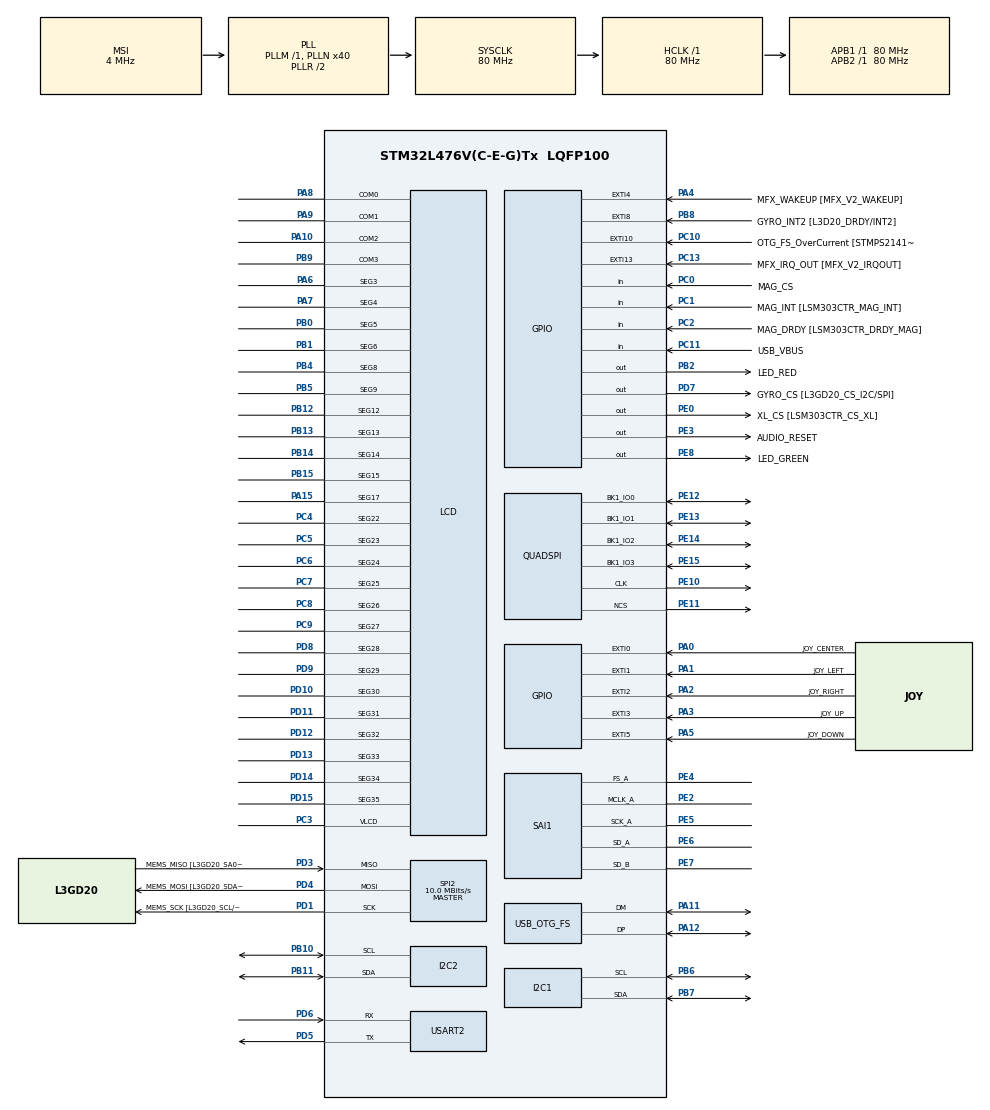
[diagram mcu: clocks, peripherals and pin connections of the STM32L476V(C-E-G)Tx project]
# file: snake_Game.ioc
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Dma.Request0=SAI1_A
Dma.SAI1_A.0.Direction=DMA_MEMORY_TO_PERIPH
Dma.SAI1_A.0.Instance=DMA2_Channel1
Dma.SAI1_A.0.MemDataAlignment=DMA_MDATAALIGN_HALFWORD
Dma.SAI1_A.0.MemInc=DMA_MINC_ENABLE
Dma.SAI1_A.0.Mode=DMA_CIRCULAR
Dma.SAI1_A.0.PeriphDataAlignment=DMA_PDATAALIGN_HALFWORD
Dma.SAI1_A.0.PeriphInc=DMA_PINC_DISABLE
Dma.SAI1_A.0.Priority=DMA_PRIORITY_HIGH
FATFS._FS_TINY=1
FATFS._MAX_SS=4096
FATFS._MIN_SS=4096
FATFS._USE_FIND=1
FATFS._USE_LABEL=1
FREERTOS.Mutexes01=qspiMutex,Dynamic,NULL
FREERTOS.Queues01=joystickInputQueue,1,uint16_t,0,Dynamic,NULL,NULL
FREERTOS.Tasks01=gameTask,0,4096,gameTaskBody,Default,NULL,Dynamic,NULL,NULL;usbTask,2,256,usbTaskBody,Default,NULL,Dynamic,NULL,NULL;audioTask,0,1024,audioTaskBody,Default,NULL,Dynamic,NULL,NULL;inputTask,0,128,inputTaskBody,Default,NULL,Dynamic,NULL,NULL
FREERTOS.configTOTAL_HEAP_SIZE=32768
I2C1.I2C_Coeff_DF=0
I2C1.I2C_Fall_Time=20
I2C1.I2C_Rise_Time=640
I2C1.Timing=0x40E03E53
I2C2.Timing=0x10909CEC
LCD.Bias=LCD_BIAS_1_3
LCD.Contrast=LCD_CONTRASTLEVEL_5
LCD.Divider=LCD_DIVIDER_31
Mcu.Family=STM32L4
Mcu.Name=STM32L476V(C-E-G)Tx
Mcu.Package=LQFP100
Mcu.UserConstants=A,0x1;B,0x2
NVIC.DMA2_Channel1_IRQn=true\:5\:0\:false\:false\:true\:true\:true\:true
NVIC.EXTI0_IRQn=true\:5\:0\:false\:false\:true\:true\:true\:true
NVIC.EXTI1_IRQn=true\:5\:0\:false\:false\:true\:true\:true\:true
NVIC.EXTI2_IRQn=true\:5\:0\:false\:false\:true\:true\:true\:true
NVIC.EXTI3_IRQn=true\:5\:0\:false\:false\:true\:true\:true\:true
NVIC.EXTI9_5_IRQn=true\:5\:0\:false\:false\:true\:true\:true\:true
NVIC.OTG_FS_IRQn=true\:5\:0\:false\:false\:true\:true\:true\:true
NVIC.PriorityGroup=NVIC_PRIORITYGROUP_4
NVIC.TIM1_UP_TIM16_IRQn=true\:0\:0\:false\:false\:true\:false\:false\:true
NVIC.TimeBase=TIM1_UP_TIM16_IRQn
NVIC.TimeBaseIP=TIM1
PA0.GPIO_Label=JOY_CENTER
PA0.GPIO_PuPd=GPIO_PULLDOWN
PA0.Signal=GPXTI0
PA1.GPIO_Label=JOY_LEFT
PA1.GPIO_PuPd=GPIO_PULLDOWN
PA1.Signal=GPXTI1
PA10.Mode=1/4 Duty Cycle
PA10.Signal=LCD_COM2
PA11.Mode=Device_Only
PA11.Signal=USB_OTG_FS_DM
PA12.Mode=Device_Only
PA12.Signal=USB_OTG_FS_DP
PA13\ (JTMS-SWDIO).Mode=Trace_Asynchronous_SW
PA13\ (JTMS-SWDIO).Signal=SYS_JTMS-SWDIO
PA14\ (JTCK-SWCLK).Mode=Trace_Asynchronous_SW
PA14\ (JTCK-SWCLK).Signal=SYS_JTCK-SWCLK
PA15\ (JTDI).Mode=SEG17
PA15\ (JTDI).Signal=LCD_SEG17
PA2.GPIO_Label=JOY_RIGHT
PA2.GPIO_PuPd=GPIO_PULLDOWN
PA2.Signal=GPXTI2
PA3.GPIO_Label=JOY_UP
PA3.GPIO_PuPd=GPIO_PULLDOWN
PA3.Signal=GPXTI3
PA4.GPIO_Label=MFX_WAKEUP [MFX_V2_WAKEUP] 
PA4.Signal=GPXTI4
PA5.GPIO_Label=JOY_DOWN
PA5.GPIO_PuPd=GPIO_PULLDOWN
PA5.Signal=GPXTI5
PA6.Mode=SEG3
PA6.Signal=LCD_SEG3
PA7.Mode=SEG4
PA7.Signal=LCD_SEG4
PA8.Mode=1/4 Duty Cycle
PA8.Signal=LCD_COM0
PA9.Mode=1/4 Duty Cycle
PA9.Signal=LCD_COM1
PB0.Mode=SEG5
PB0.Signal=LCD_SEG5
PB1.Mode=SEG6
PB1.Signal=LCD_SEG6
PB10.Mode=I2C
PB10.Signal=I2C2_SCL
PB11.Mode=I2C
PB11.Signal=I2C2_SDA
PB12.Mode=SEG12
PB12.Signal=LCD_SEG12
PB13.Mode=SEG13
PB13.Signal=LCD_SEG13
PB14.Mode=SEG14
PB14.Signal=LCD_SEG14
PB15.Mode=SEG15
PB15.Signal=LCD_SEG15
PB2.GPIO_Label=LED_RED
PB2.GPIO_PuPd=GPIO_PULLUP
PB2.Signal=GPIO_Output
PB3\ (JTDO-TRACESWO).Mode=Trace_Asynchronous_SW
PB3\ (JTDO-TRACESWO).Signal=SYS_JTDO-SWO
PB4\ (NJTRST).Mode=SEG8
PB4\ (NJTRST).Signal=LCD_SEG8
PB5.Mode=SEG9
PB5.Signal=LCD_SEG9
PB6.Mode=I2C
PB6.Signal=I2C1_SCL
PB7.Mode=I2C
PB7.Signal=I2C1_SDA
PB8.GPIO_Label=GYRO_INT2 [L3D20_DRDY/INT2] 
PB8.GPIO_ModeDefaultEXTI=GPIO_MODE_EVT_RISING
PB8.Signal=GPXTI8
PB9.Mode=1/4 Duty Cycle
PB9.Signal=LCD_COM3
PC0.GPIO_Label=MAG_CS
PC0.Signal=GPIO_Input
PC1.GPIO_Label=MAG_INT [LSM303CTR_MAG_INT] 
PC1.Signal=GPIO_Input
PC10.GPIO_Label=OTG_FS_OverCurrent [STMPS2141STR_FAULT] 
PC10.Signal=GPXTI10
PC11.GPIO_Label=USB_VBUS
PC11.Signal=GPIO_Input
PC13.GPIO_Label=MFX_IRQ_OUT [MFX_V2_IRQOUT] 
PC13.Signal=GPXTI13
PC14-OSC32_IN\ (PC14).Mode=LSE-External-Oscillator
PC14-OSC32_IN\ (PC14).Signal=RCC_OSC32_IN
PC15-OSC32_OUT\ (PC15).Mode=LSE-External-Oscillator
PC15-OSC32_OUT\ (PC15).Signal=RCC_OSC32_OUT
PC2.GPIO_Label=MAG_DRDY [LSM303CTR_DRDY_MAG] 
PC2.Signal=GPIO_Input
PC3.Mode=1/4 Duty Cycle
PC3.Signal=LCD_VLCD
PC4.Mode=SEG22
PC4.Signal=LCD_SEG22
PC5.Mode=SEG23
PC5.Signal=LCD_SEG23
PC6.Mode=SEG24
PC6.Signal=LCD_SEG24
PC7.Mode=SEG25
PC7.Signal=LCD_SEG25
PC8.Mode=SEG26
PC8.Signal=LCD_SEG26
PC9.Mode=SEG27
PC9.Signal=LCD_SEG27
PD1.GPIO_Label=MEMS_SCK [L3GD20_SCL/SPC] 
PD1.Mode=Full_Duplex_Master
PD1.Signal=SPI2_SCK
PD10.Mode=SEG30
PD10.Signal=LCD_SEG30
PD11.Mode=SEG31
PD11.Signal=LCD_SEG31
PD12.Mode=SEG32
PD12.Signal=LCD_SEG32
PD13.Mode=SEG33
PD13.Signal=LCD_SEG33
PD14.Mode=SEG34
PD14.Signal=LCD_SEG34
PD15.Mode=SEG35
PD15.Signal=LCD_SEG35
PD3.GPIO_Label=MEMS_MISO [L3GD20_SA0/SDO] 
PD3.Mode=Full_Duplex_Master
PD3.Signal=SPI2_MISO
PD4.GPIO_Label=MEMS_MOSI [L3GD20_SDA/SDI/SDO] 
PD4.Mode=Full_Duplex_Master
PD4.Signal=SPI2_MOSI
PD5.Mode=Asynchronous
PD5.Signal=USART2_TX
PD6.Mode=Asynchronous
PD6.Signal=USART2_RX
PD7.GPIO_Label=GYRO_CS [L3GD20_CS_I2C/SPI] 
PD7.Signal=GPIO_Output
PD8.Mode=SEG28
PD8.Signal=LCD_SEG28
PD9.Mode=SEG29
PD9.Signal=LCD_SEG29
PE0.GPIO_Label=XL_CS [LSM303CTR_CS_XL] 
PE0.Signal=GPIO_Output
PE10.Mode=Single Bank
PE10.Signal=QUADSPI_CLK
PE11.Mode=Single Bank
PE11.Signal=QUADSPI_NCS
PE12.Mode=Single Bank
PE12.Signal=QUADSPI_BK1_IO0
PE13.Mode=Single Bank
PE13.Signal=QUADSPI_BK1_IO1
PE14.Mode=Single Bank
PE14.Signal=QUADSPI_BK1_IO2
PE15.Mode=Single Bank
PE15.Signal=QUADSPI_BK1_IO3
PE2.Mode=SAI_A_MasterWithClock
PE2.Signal=SAI1_MCLK_A
PE3.GPIO_Label=AUDIO_RESET
PE3.Signal=GPIO_Output
PE4.Mode=SAI_A_MasterWithClock
PE4.Signal=SAI1_FS_A
PE5.Mode=SAI_A_MasterWithClock
PE5.Signal=SAI1_SCK_A
PE6.Mode=SAI_A_MasterWithClock
PE6.Signal=SAI1_SD_A
PE7.Mode=SAI_B_SyncSlave
PE7.Signal=SAI1_SD_B
PE8.GPIO_Label=LED_GREEN
PE8.GPIO_PuPd=GPIO_PULLUP
PE8.Signal=GPIO_Output
ProjectManager.HeapSize=0x200
ProjectManager.StackSize=0x400
ProjectManager.TargetToolchain=STM32CubeIDE
QUADSPI.ClockPrescaler-Single\ Bank=255
QUADSPI.FifoThreshold-Single\ Bank=1
QUADSPI.FlashSize-Single\ Bank=0x17
RCC.ADCFreq_Value=96000000
RCC.AHBFreq_Value=80000000
RCC.APB1Freq_Value=80000000
RCC.APB1TimFreq_Value=80000000
RCC.APB2Freq_Value=80000000
RCC.APB2TimFreq_Value=80000000
RCC.CortexFreq_Value=80000000
RCC.HCLKFreq_Value=80000000
RCC.HSE_VALUE=8000000
RCC.HSI_VALUE=16000000
RCC.MSIClockRange=RCC_MSIRANGE_6
RCC.MSI_VALUE=4000000
RCC.PLLN=40
RCC.PLLSAI1N=48
RCC.PLLSAI1P=RCC_PLLP_DIV17
RCC.PLLSAI1Q=RCC_PLLQ_DIV4
RCC.RTCClockSelection=RCC_RTCCLKSOURCE_LSE
RCC.SYSCLKFreq_VALUE=80000000
RCC.SYSCLKSource=RCC_SYSCLKSOURCE_PLLCLK
RCC.USBFreq_Value=48000000
RCC.VCOOutputFreq_Value=160000000
SAI1.ActiveFrameLength-SAI_A_MasterWithClock=16
SAI1.AudioFrequency-SAI_A_MasterWithClock=SAI_AUDIO_FREQUENCY_44K
SAI1.ClockStrobing-SAI_A_MasterWithClock=SAI_CLOCKSTROBING_RISINGEDGE
SAI1.DataSize-SAI_A_MasterWithClock=SAI_DATASIZE_16
SAI1.ErrorAudioFreq-SAI_A_MasterWithClock=0.26 %
SAI1.FIFOThreshold-SAI_A_MasterWithClock=SAI_FIFOTHRESHOLD_1QF
SAI1.FSDefinition-SAI_A_MasterWithClock=SAI_FS_CHANNEL_IDENTIFICATION
SAI1.FSOffset-SAI_A_MasterWithClock=SAI_FS_BEFOREFIRSTBIT
SAI1.FrameLength-SAI_A_MasterWithClock=32
SAI1.FrameLength-SAI_B_SyncSlave=32
SAI1.Instance-SAI_A_MasterWithClock=SAI$Index_Block_A
SAI1.Instance-SAI_B_SyncSlave=SAI$Index_Block_B
SAI1.MClockEnable-SAI_A_MasterWithClock=SAI_MASTERCLOCK_ENABLE
SAI1.OutputDrive-SAI_A_MasterWithClock=SAI_OUTPUTDRIVE_ENABLE
SAI1.RealAudioFreq-SAI_A_MasterWithClock=44.117 KHz
SAI1.SlotActive-SAI_A_MasterWithClock=0x00000003
SAI1.SlotNumber-SAI_A_MasterWithClock=2
SAI1.VirtualMode-SAI_A_MasterWithClock=VM_MASTER
SAI1.VirtualMode-SAI_B_SyncSlave=VM_SLAVE
SAI1.VirtualSlotActive-SAI_A_MasterWithClock=SAI_SLOT_USERSETTING
SAI1.VirtualSlotActive0-SAI_A_MasterWithClock=true
SAI1.VirtualSlotActive1-SAI_A_MasterWithClock=true
SPI2.BaudRatePrescaler=SPI_BAUDRATEPRESCALER_8
SPI2.CalculateBaudRate=10.0 MBits/s
SPI2.DataSize=SPI_DATASIZE_8BIT
SPI2.Direction=SPI_DIRECTION_2LINES
SPI2.Mode=SPI_MODE_MASTER
SPI2.VirtualType=VM_MASTER
USART2.VirtualMode-Asynchronous=VM_ASYNC
USB_DEVICE.CLASS_NAME_FS=MSC
USB_DEVICE.MSC_MEDIA_PACKET=4096
USB_DEVICE.USBD_LPM_ENABLED=0
USB_DEVICE.VirtualMode=Msc
USB_DEVICE.VirtualModeFS=Msc_FS
USB_OTG_FS.VirtualMode=Device_Only
VP_FATFS_VS_Generic.Mode=User_defined
VP_FREERTOS_VS_CMSIS_V1.Mode=CMSIS_V1
VP_SYS_VS_tim1.Mode=TIM1
VP_USB_DEVICE_VS_USB_DEVICE_MSC_FS.Mode=MSC_FS
board=Audio_player2

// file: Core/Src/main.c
/* USER CODE BEGIN Header */
/**
 ******************************************************************************
 * @file           : main.c
 * @brief          : Main program body
 ******************************************************************************
 * @attention
 *
 * <h2><center>&copy; Copyright (c) 2020 STMicroelectronics.
 * All rights reserved.</center></h2>
 *
 * This software component is licensed by ST under Ultimate Liberty license
 * SLA0044, the "License"; You may not use this file except in compliance with
 * the License. You may obtain a copy of the License at:
 *                             www.st.com/SLA0044
 *
 ******************************************************************************
 */
/* USER CODE END Header */

#include "main.h"
#include "cmsis_os.h"
#include "dma.h"
#include "fatfs.h"
#include "i2c.h"
#include "lcd.h"
#include "quadspi.h"
#include "sai.h"
#include "spi.h"
#include "usart.h"
#include "usb_device.h"
#include "gpio.h"

/* USER CODE BEGIN Includes */
// ***** Librerías comunes *****
#include <stdio.h>
#include <string.h>
#include <stdlib.h>
#include <stdbool.h>
#include <time.h>

// ***** Librerías del BSP *****
#include "stm32l476g_discovery.h"
#include "stm32l476g_discovery_glass_lcd.h"
#include "stm32l476g_discovery_compass.h"
#include "stm32l476g_discovery_gyroscope.h"

// ***** Librerías de la pantalla oled *****
#include "ssd1306.h"
//#include "ssd1306_tests.h"

/* USER CODE END Includes */

/* USER CODE BEGIN PV */
// ***** Parámetros de la pantalla *****
const int width = 128;
const int height = 64;

// ***** Parámetros del menu *****
SSD1306_COLOR color = Black;	// Color de fondo del texto
int menu = 0;	// Indice del menu

// ***** Parámetros del juego *****
bool gameover;	// Bandera de Game Over
int x, y, score;	// Coordenadas de la pantalla y variable para los puntos
int fruitX[3], fruitY[3];	// Arrays con las coordenadas de las frutas
int snakeX[256], snakeY[256]; // Arrays con las coordenadas del cuerpo de la serpiente
int nTail;	// Número de pixeles que forman la cola de la serpiente
int state, prev_state;	// Estado en el que nos encontramos y el anterior a este

// ***** Variables del sistema de archivos Fat y del USB *****
FIL                     File;						// Handle del archivo
FATFS                   FatFs;						// Handle del sistema de archivos

/* USER CODE END PV */

void SystemClock_Config(void);
void MX_FREERTOS_Init(void);
/* USER CODE BEGIN PFP */

// ***** Funciones de Audio *****
void AudioPlayer_Start(const TCHAR* file_name, bool bg_music, bool aflag);

// ***** Funciones del Juego *****
void Setup();		// Función para establecer las condiciones iniciales
void DrawOled();	// Función para dibujar la pantalla oled
void Algoritmo();	// Función que controla la ejecución del juego
void Fruta();		// Función para crear las frutas en la pantalla
void GameOver();	// Función para el estado de Game Over
void Leaderboard();	// Función para mostrar las mejores puntuaciones conseguidas
/* USER CODE END PFP */

int main(void)
{

  /* MCU Configuration--------------------------------------------------------*/

  /* Reset of all peripherals, Initializes the Flash interface and the Systick. */
  HAL_Init();

  /* Configure the system clock */
  SystemClock_Config();

  /* Initialize all configured peripherals */
  MX_GPIO_Init();
  MX_DMA_Init();
  MX_I2C1_Init();
  MX_I2C2_Init();
  MX_LCD_Init();
  MX_QUADSPI_Init();
  MX_SAI1_Init();
  MX_SPI2_Init();
  MX_USART2_UART_Init();
  MX_FATFS_Init();
  /* USER CODE BEGIN 2 */

  // Inicializamos los módulos BSP
  //BSP_COMPASS_Init();
  BSP_GYRO_Init();
  BSP_LCD_GLASS_Init();

  /* USER CODE END 2 */

  /* Call init function for freertos objects (in freertos.c) */
  MX_FREERTOS_Init();
  /* Start scheduler */
  //osKernelStart();

  /* We should never get here as control is now taken by the scheduler */
  /* Infinite loop */
  /* USER CODE BEGIN WHILE */

  // Mostramos la pantalla de inicio
	ssd1306_Init();	// Iniciamos la comunicación con la pantalla oled
	ssd1306_Fill(Black);	// Dibujamos toda la pantalla de negro
	ssd1306_SetCursor(24, 4);	// Situamos el cursor en las coordenadas indicadas
	ssd1306_WriteString("SNAKE", Font_16x26, White);	// Escribimos el string con la fuente
	ssd1306_SetCursor(24, 34);						 	// y el color indicado
	ssd1306_WriteString("START", Font_16x26, White);	// Repetimos para cada string
	ssd1306_UpdateScreen();	// Actualizamos la pantalla con lo que hemos dibujado

	while (1)
	{
    /* USER CODE END WHILE */

    /* USER CODE BEGIN 3 */

		// ***** Pantalla de Inicio *****
		if (menu == 0)
		{
			for(int i = 0; i < 100; i++)	// Realizamos una espera de 500 ms
			{
				JOYState_TypeDef JoyState = BSP_JOY_GetState();	// Obetenemos la entrada del DPAD

				if(JoyState == JOY_SEL){	// Si el usuario pulsa el botón central mostramos el menú
					menu = 1;	// Cambiamos el índice del menú para indicar que hemos entrado
					ssd1306_Fill(Black);	// Y dibujamos el menú de inicio
					ssd1306_SetCursor(42, 1);
					ssd1306_WriteString("MENU", Font_11x18, White);
					ssd1306_SetCursor(13, 20);
					ssd1306_WriteString("DPAD", Font_11x18, White);
					ssd1306_SetCursor(70, 20);
					ssd1306_WriteString("GYRO", Font_11x18, White);
					ssd1306_SetCursor(31, 40);
					ssd1306_WriteString("SCORES", Font_11x18, White);
					ssd1306_UpdateScreen();
					HAL_Delay(100);
					break;
				}
				HAL_Delay(5);
			}

			if(menu == 0)	// Cada 500 ms cambiamos el color de fondo del botón START
			{
				ssd1306_SetCursor(24, 34);
				ssd1306_WriteString("START", Font_16x26, color);
				ssd1306_UpdateScreen();
			}

			if (color == Black)	// Con este IF intercambiamos el color de fondo
				color = White;	// del botón de START para crear el efecto de intermitencia
			else
				color = Black;
		}
		else // ***** Menu principal *****
		{
			JOYState_TypeDef JoyState = BSP_JOY_GetState();

			switch(JoyState) {	// Leemos el valor de entrada del DPAD y cambiamos
			case JOY_LEFT:		// la selección del menú de acuerdo a eso
				if(menu == 2)
					menu = 1;
				break;
			case JOY_RIGHT:
				if(menu == 1)
					menu = 2;
				break;
			case JOY_UP:
				if(menu == 3)
					menu = 1;
				break;
			case JOY_DOWN:
				if(menu == 1 || menu == 2)
					menu = 3;
				break;
			case JOY_SEL:
				if(menu == 1)			// Si estamos en la opción 1 ejecutamos el juego usando
				{						// como entrada el DPAD para jugar
					HAL_Delay(100);
					Setup();
					DrawOled();			// Dibujamos la pantalla de juego
					osKernelStart();	// e iniciamos el planificador
				}
				else if(menu == 2)		// Si estamos en la opción 2 ejecutamos el juego usando
				{						// como entrada el Giroscopio o el Acelerómetro para jugar
					HAL_Delay(100);
					Setup();
					DrawOled();			// Dibujamos la pantalla de juego
					osKernelStart();	// e iniciamos el planificador
				}
				else if(menu == 3)		// Si estamos en la opción 3 ejecutamos la función para
				{						// mostrar las mejores puntuaciones que estén guardadas
					HAL_Delay(100);
					Leaderboard();
				}
				break;
			default:	// Si no hay entrada, no ejecutamos nada
				break;
			}

			if(menu == 1)	// Mostramos la opción de DPAD como seleccionada
			{
				ssd1306_Fill(Black);
				ssd1306_SetCursor(42, 1);
				ssd1306_WriteString("MENU", Font_11x18, White);
				ssd1306_SetCursor(13, 20);
				ssd1306_WriteString("DPAD", Font_11x18, Black);
				ssd1306_SetCursor(70, 20);
				ssd1306_WriteString("GYRO", Font_11x18, White);
				ssd1306_SetCursor(31, 40);
				ssd1306_WriteString("SCORES", Font_11x18, White);
				ssd1306_UpdateScreen();
			}
			else if(menu == 2)	// Mostramos la opción de GYRO como seleccionada
			{
				ssd1306_Fill(Black);
				ssd1306_SetCursor(42, 1);
				ssd1306_WriteString("MENU", Font_11x18, White);
				ssd1306_SetCursor(13, 20);
				ssd1306_WriteString("DPAD", Font_11x18, White);
				ssd1306_SetCursor(70, 20);
				ssd1306_WriteString("GYRO", Font_11x18, Black);
				ssd1306_SetCursor(31, 40);
				ssd1306_WriteString("SCORES", Font_11x18, White);
				ssd1306_UpdateScreen();
			}
			else if(menu == 3)	// Mostramos la opción de SCORES como seleccionada
			{
				ssd1306_Fill(Black);
				ssd1306_SetCursor(42, 1);
				ssd1306_WriteString("MENU", Font_11x18, White);
				ssd1306_SetCursor(13, 20);
				ssd1306_WriteString("DPAD", Font_11x18, White);
				ssd1306_SetCursor(70, 20);
				ssd1306_WriteString("GYRO", Font_11x18, White);
				ssd1306_SetCursor(31, 40);
				ssd1306_WriteString("SCORES", Font_11x18, Black);
				ssd1306_UpdateScreen();
			}
		}

		// Comprobamos si se ha conectado el USB, y en caso de que sí iniciamos el scheduler
		if ((HAL_GPIO_ReadPin(USB_VBUS_GPIO_Port, USB_VBUS_Pin) != GPIO_PIN_RESET) && menu == 0)
		{
			osKernelStart();
		}

	}
  /* USER CODE END 3 */
}

void SystemClock_Config(void)
{
  RCC_OscInitTypeDef RCC_OscInitStruct = {0};
  RCC_ClkInitTypeDef RCC_ClkInitStruct = {0};
  RCC_PeriphCLKInitTypeDef PeriphClkInit = {0};

  /** Configure LSE Drive Capability
  */
  HAL_PWR_EnableBkUpAccess();
  __HAL_RCC_LSEDRIVE_CONFIG(RCC_LSEDRIVE_LOW);
  /** Initializes the CPU, AHB and APB busses clocks
  */
  RCC_OscInitStruct.OscillatorType = RCC_OSCILLATORTYPE_LSE|RCC_OSCILLATORTYPE_MSI;
  RCC_OscInitStruct.LSEState = RCC_LSE_ON;
  RCC_OscInitStruct.MSIState = RCC_MSI_ON;
  RCC_OscInitStruct.MSICalibrationValue = 0;
  RCC_OscInitStruct.MSIClockRange = RCC_MSIRANGE_6;
  RCC_OscInitStruct.PLL.PLLState = RCC_PLL_ON;
  RCC_OscInitStruct.PLL.PLLSource = RCC_PLLSOURCE_MSI;
  RCC_OscInitStruct.PLL.PLLM = 1;
  RCC_OscInitStruct.PLL.PLLN = 40;
  RCC_OscInitStruct.PLL.PLLP = RCC_PLLP_DIV7;
  RCC_OscInitStruct.PLL.PLLQ = RCC_PLLQ_DIV2;
  RCC_OscInitStruct.PLL.PLLR = RCC_PLLR_DIV2;
  if (HAL_RCC_OscConfig(&RCC_OscInitStruct) != HAL_OK)
  {
    Error_Handler();
  }
  /** Initializes the CPU, AHB and APB busses clocks
  */
  RCC_ClkInitStruct.ClockType = RCC_CLOCKTYPE_HCLK|RCC_CLOCKTYPE_SYSCLK
                              |RCC_CLOCKTYPE_PCLK1|RCC_CLOCKTYPE_PCLK2;
  RCC_ClkInitStruct.SYSCLKSource = RCC_SYSCLKSOURCE_PLLCLK;
  RCC_ClkInitStruct.AHBCLKDivider = RCC_SYSCLK_DIV1;
  RCC_ClkInitStruct.APB1CLKDivider = RCC_HCLK_DIV1;
  RCC_ClkInitStruct.APB2CLKDivider = RCC_HCLK_DIV1;

  if (HAL_RCC_ClockConfig(&RCC_ClkInitStruct, FLASH_LATENCY_4) != HAL_OK)
  {
    Error_Handler();
  }
  PeriphClkInit.PeriphClockSelection = RCC_PERIPHCLK_RTC|RCC_PERIPHCLK_USART2
                              |RCC_PERIPHCLK_SAI1|RCC_PERIPHCLK_I2C1
                              |RCC_PERIPHCLK_I2C2|RCC_PERIPHCLK_USB;
  PeriphClkInit.Usart2ClockSelection = RCC_USART2CLKSOURCE_PCLK1;
  PeriphClkInit.I2c1ClockSelection = RCC_I2C1CLKSOURCE_PCLK1;
  PeriphClkInit.I2c2ClockSelection = RCC_I2C2CLKSOURCE_PCLK1;
  PeriphClkInit.Sai1ClockSelection = RCC_SAI1CLKSOURCE_PLLSAI1;
  PeriphClkInit.RTCClockSelection = RCC_RTCCLKSOURCE_LSE;
  PeriphClkInit.UsbClockSelection = RCC_USBCLKSOURCE_PLLSAI1;
  PeriphClkInit.PLLSAI1.PLLSAI1Source = RCC_PLLSOURCE_MSI;
  PeriphClkInit.PLLSAI1.PLLSAI1M = 1;
  PeriphClkInit.PLLSAI1.PLLSAI1N = 48;
  PeriphClkInit.PLLSAI1.PLLSAI1P = RCC_PLLP_DIV17;
  PeriphClkInit.PLLSAI1.PLLSAI1Q = RCC_PLLQ_DIV4;
  PeriphClkInit.PLLSAI1.PLLSAI1R = RCC_PLLR_DIV2;
  PeriphClkInit.PLLSAI1.PLLSAI1ClockOut = RCC_PLLSAI1_SAI1CLK|RCC_PLLSAI1_48M2CLK;
  if (HAL_RCCEx_PeriphCLKConfig(&PeriphClkInit) != HAL_OK)
  {
    Error_Handler();
  }
  /** Configure the main internal regulator output voltage
  */
  if (HAL_PWREx_ControlVoltageScaling(PWR_REGULATOR_VOLTAGE_SCALE1) != HAL_OK)
  {
    Error_Handler();
  }
  /** Enable MSI Auto calibration
  */
  HAL_RCCEx_EnableMSIPLLMode();
}

/* USER CODE BEGIN 4 */
void Setup()	//  Función de inicialización de las variables del juego
{
	char string[100];

	// Variables
	gameover = false;
	state = 0;
	prev_state = 0;
	x = width / 2;
	y = height / 2;
	nTail = 0;

	// Reseteamos la puntuación
	score = 0;
	sprintf(string, "%d", score);
	BSP_LCD_GLASS_DisplayString((uint8_t *)string);

	// Reseteamos las coordenadas de las frutas
	fruitX[0] = 0; fruitY[0] = 0;
	fruitX[1] = 0; fruitY[1] = 0;
	fruitX[2] = 0; fruitY[2] = 0;
	Fruta();	// Generamos 3 nuevas frutas
}

void DrawOled(){
	ssd1306_Fill(Black);	// Limpiamos la pantalla

	// Dibujamos los muros
	for (int i = 0; i < width ; i++){
		for (int j = 0; j < height; j++)
		{
			if (i == 0)
				ssd1306_DrawPixel(i, j, White);
			else if (i == width - 1)
				ssd1306_DrawPixel(i, j, White);
			else if (j == 0)
				ssd1306_DrawPixel(i, j, White);
			else if (j == height - 1)
				ssd1306_DrawPixel(i, j, White);
		}
	}

	// Dibujamos las frutas y la serpiente
	for (int i = 0; i < width; i++)
	{
		for (int j = 0; j < height; j++)
		{
			if (i == x && j == y)
				ssd1306_DrawPixel(i, j, White); // Cola
			else if ((i == fruitX[0] && j == fruitY[0]) || (i == fruitX[1] && j == fruitY[1]) || (i == fruitX[2] && j == fruitY[2]))
				ssd1306_DrawPixel(i, j, White); // Coincide con alguna de las frutas
			else
			{
				for (int k = 0; k < nTail; k++)
				{
					if (snakeX[k] == i && snakeY[k] == j)
					{
						ssd1306_DrawPixel(i, j, White);
					}
				}
			}
		}
	}

	// Juego en pausa cuando se pulsa el botón central
	if (state == 5 && prev_state!=0 && gameover==false)
	{
		ssd1306_SetCursor(36, 22);
		ssd1306_WriteString("PAUSA", Font_11x18, White);
	}

	ssd1306_UpdateScreen();
}

void Algoritmo(){	// Función principal que define el funcionamiento
	int prevX, prevY, prev2X, prev2Y;
	char string[100];

	// Actualizamos la cola
	if (state != 5)
	{
		prevX = snakeX[0];
		prevY = snakeY[0];
		snakeX[0] = x;
		snakeY[0] = y;

		for (int i = 1; i < nTail; i++)
		{
			prev2X = snakeX[i];
			prev2Y = snakeY[i];
			snakeX[i] = prevX;
			snakeY[i] = prevY;
			prevX = prev2X;
			prevY = prev2Y;
		}
	}

	// Izquierda - Variación en el eje X
	if(state == 1){
		x -= 1;
		prev_state = 1;
	}//Derecha
	else if(state == 2){
		x += 1;
		prev_state = 2;
	}// Arriba - Variación en el eje Y
	else if(state == 3){
		y -= 1;
		prev_state = 3;
	}// Abajo
	else if(state == 4){
		y += 1;
		prev_state = 4;
	}

	// Situaciones de Game Over
	if (x >= (width-1)) // Chocarse con las paredes laterales
		gameover = true;
	else if (x <= 0)
		gameover = true;

	if (y >= (height-1)) // Chocarse con la pared superior o inferior
		gameover = true;
	else if (y <= 0)
		gameover = true;

	for (int i = 0; i < nTail; i++) // Choca con su propia cola
	{
		if (snakeX[i] == x && snakeY[i] == y)
			gameover = true;
	}

	// Comprobamos si se ha comido una fruta
	for (int i = 0; i < 3; i++)
	{
		if (x == fruitX[i] && y == fruitY[i])
		{
			AudioPlayer_Start("fruit.wav", 0, 1);	// Reproducimos el audio asignada a las frutas
			score += 10;	// Sumamos 10 puntos a la puntuación
			sprintf(string, "%d", score);
			BSP_LCD_GLASS_DisplayString((uint8_t *)string);	// Actualizamos la puntuación en el LCD
			Fruta();	// Generamos una nueva fruta
			nTail++;	// Aumentamos longitud de la cola
		}
	}
}

void Fruta(){	// Genera una fruta en una posición aleatoria

	for( int i=0; i < 3; i++)	// Comprobamos cuantas frutas faltan y si se encuentran dentro de los límites
	{
		if(fruitX[i] <= 0 || fruitY[i] <= 0 || fruitX[i] >= height || fruitX[i] >= width || (fruitX[i] == x && fruitY[i] == y)){
			fruitX[i] = (rand()%width);
			fruitY[i] = (rand()%height);
			i--;
		}
	}
}

void GameOver(){		// Pantalla de GameOver

	char string[100];
	char alphabet[] = "ABCDEFGHIJKLMNOPQRSTUVWXYZ";	// String para obtener las letras en función de su posición
	int char_sel[3] = { 0, 0, 0};	// Variable para guardar la selección de letras
	int p = 0;

	FIL File;	// Establecemos la variable para abrir el archivo
	uint br;

	char players[80];	// String para cargar las puntuaciones guardadas
	char player[7];		// String del jugador actual
	char buffer[7];
	int ctrl = 0;

	color = Black;		// Declaramos el color de la fuente de texto como negro

	// Dibujamos la pantalla principal de Game Over
	ssd1306_Fill(Black);
	ssd1306_SetCursor(14, 1);
	ssd1306_WriteString("GAME OVER", Font_11x18, White);
	ssd1306_SetCursor(2, 22);
	ssd1306_WriteString("Name:", Font_11x18, White);
	ssd1306_SetCursor(74, 22);
	ssd1306_WriteString("A", Font_11x18, White);
	ssd1306_SetCursor(87, 22);
	ssd1306_WriteString("A", Font_11x18, White);
	ssd1306_SetCursor(100, 22);
	ssd1306_WriteString("A", Font_11x18, White);
	ssd1306_SetCursor(2, 42);
	sprintf(string, "Score: %d", score);
	ssd1306_WriteString(string, Font_11x18, White);
	ssd1306_UpdateScreen();

	// Introducción de las iniciales del jugador
	while(1)
	{
		for (int t=0; t<5; t++)
		{
			JOYState_TypeDef JoyState = BSP_JOY_GetState();

			switch(JoyState) {	// Leemos la entrada del DPAD y aumentamos o disminuimos
				case JOY_LEFT:	// el índice de cada de las letras
					if(p > 0)
						p--;
					break;
				case JOY_RIGHT:
					if(p < 2)
						p++;
					break;
				case JOY_UP:
					if(char_sel[p] < 25)
						char_sel[p]++;
					break;
				case JOY_DOWN:
					if(char_sel[p] > 0)
						char_sel[p]--;
					break;
				case JOY_SEL:	// Si el usuario presiona el boton central, comprobamos la puntuación

					/* Montamos el sistema de archivos del módulo FatFs */
					if(f_mount(&FatFs, (TCHAR const*)USERPath, 1) != FR_OK)
					{
						/* Error de inicialización de FatFs */
						if (f_mkfs((TCHAR const*)USERPath, 0, 128, NULL, 0) != FR_OK)
						{
							Error_Handler();
						}
						else {
							/* Segundo intento de montar el sistema de archivos */
							if(f_mount(&FatFs, (TCHAR const*)USERPath, 1) != FR_OK)
							{
								Error_Handler();
							}
						}
					}

					/* FatFS read */
					if (f_open(&File, "score.txt", FA_READ) == FR_OK) { // Abrimos el archivo de puntuaciones
					  f_read(&File, players, 72, &br);	// Leemos el contenido y lo guardamos en el buffer
					  f_close(&File);
					}

					// Corregimos el string si es menor de 100, ya que tiene un dígito menos
					if (score >= 100)
						sprintf(player, "%c%c%c %d", alphabet[char_sel[0]], alphabet[char_sel[1]], alphabet[char_sel[2]], score);
					else
						sprintf(player, "%c%c%c  %d", alphabet[char_sel[0]], alphabet[char_sel[1]], alphabet[char_sel[2]], score);

					/* FatFS file write - Escribimos las puntuaciones en el archivo de nuevo */
					if (f_open(&File, "score.txt", FA_CREATE_ALWAYS | FA_WRITE) == FR_OK) {

						// Este algoritmo comprobará la puntuación obtenida con las guardadas
						// y en el caso de que sea más alta la añadirá a la lista
						for(int i=0; i<8; i++){
							for(int j=0; j<7; j++){
								buffer[j] = players[j+(i-ctrl)*9];
							}

							// Comprobamos si la puntuación es más alta
							if ((player[4] > buffer[4]) && ctrl==0)
							{
								for(int k=0; k<7; k++)
									buffer[k] = player[k];
								ctrl = 1;
							}
							else if ((player[4] == buffer[4]) && ctrl==0)
							{
								if(player[5] > buffer[5])
								{
									for(int k=0; k<7; k++)
										buffer[k] = player[k];
									ctrl = 1;
								}
								else if (player[5] == buffer[5])
								{
									if(player[6] >= buffer[6])
									{
										for(int k=0; k<7; k++)
											buffer[k] = player[k];
										ctrl = 1;
									}
								}
							}

							// Añadimos al jugador
							f_printf(&File, buffer);
							f_printf(&File, "\n");
						}

						f_close(&File);
					}

					// Reiniciamos a la pantalla de inicio, como en las máquinas arcade antiguas
					NVIC_SystemReset();
					break;
				default:
					break;
			}

			// Impresión en pantalla de las iniciales
			for (int i=0; i<3; i++)
			{
				char letter = alphabet[char_sel[i]];

				if (i == p)
				{
					ssd1306_SetCursor(74+i*13, 22);
					ssd1306_WriteString(&letter, Font_11x18, color);
				}
				else
				{
					ssd1306_SetCursor(74+i*13, 22);
					ssd1306_WriteString(&letter, Font_11x18, White);
				}
			}

			ssd1306_UpdateScreen();
			HAL_Delay(50);
		}

		// Rotación de color de las letras
		if (color == Black)
			color = White;
		else
			color = Black;
	}
}

void Leaderboard(){	// Función para mostrar las puntuaciones guardadas
	char players[80];
	char buffer[10];

	// Variables para el control del dibujado en la pantalla
	int uix = 7;
	int uiy = 21;
	int ctrl = 0;

	// Variables del archivo de puntuaciones
	FIL File;
	FATFS FatFs;
	uint br;

	/* init code for USB_DEVICE - Iniciamos el periférico USB */
	MX_USB_DEVICE_Init();

	/* Register the file system object to the FatFs module */
	if (f_mount(&FatFs, (TCHAR const*) USERPath, 1) != FR_OK) {
	  /* FatFs Initialization Error */
	  if (f_mkfs((TCHAR const*)USERPath, 0, 128, NULL, 0) != FR_OK) {
		  Error_Handler();
	  } else {
		  /* Second trial to register the file system object */
		  if (f_mount(&FatFs, (TCHAR const*) USERPath, 1) != FR_OK) {
			  Error_Handler();
		  }
	  }
	}

	/* FatFS read - Leemos el archivo de puntuaciones*/
	if (f_open(&File, "score.txt", FA_READ) == FR_OK) {
	  f_read(&File, players, 72, &br);
	  puts(players);
	  f_close(&File);
	}

	// Mostramos las puntuaciones guardadas
	ssd1306_Fill(Black);
	ssd1306_SetCursor(3, 1);
	ssd1306_WriteString("BEST SCORES", Font_11x18, White);

	for(int i=0; i<8; i++){
		for(int j=0; j<7; j++){
			buffer[j] = players[j+(i-ctrl)*9];
		}

		// Imprimimos la puntuación
		ssd1306_SetCursor(uix, uiy);
		ssd1306_WriteString(buffer, Font_7x10, White);

		// Variamos la posición del cursor
		if (i<3)
			uix = 7;
		else
			uix = 63;

		if (uiy <51)
			uiy = uiy+10;
		else
			uiy = 21;
	}

	ssd1306_UpdateScreen();

	// Si presionamos el botón central volvemos al menu
	while(1)
	{
		JOYState_TypeDef JoyState = BSP_JOY_GetState();
		if(JoyState == JOY_SEL){
			HAL_Delay(100);
			return;
		}
	}
}

/* USER CODE END 4 */

 /**
  * @brief  Period elapsed callback in non blocking mode
  * @note   This function is called  when TIM1 interrupt took place, inside
  * HAL_TIM_IRQHandler(). It makes a direct call to HAL_IncTick() to increment
  * a global variable "uwTick" used as application time base.
  * @param  htim : TIM handle
  * @retval None
  */
void HAL_TIM_PeriodElapsedCallback(TIM_HandleTypeDef *htim)
{
  if (htim->Instance == TIM1) {
    HAL_IncTick();
  }
}

void Error_Handler(void)
{
}

/************************ (C) COPYRIGHT STMicroelectronics *****END OF FILE****/

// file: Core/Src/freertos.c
/* USER CODE BEGIN Header */
/**
 ******************************************************************************
 * File Name          : freertos.c
 * Description        : Code for freertos applications
 ******************************************************************************
 * @attention
 *
 * <h2><center>&copy; Copyright (c) 2020 STMicroelectronics.
 * All rights reserved.</center></h2>
 *
 * This software component is licensed by ST under Ultimate Liberty license
 * SLA0044, the "License"; You may not use this file except in compliance with
 * the License. You may obtain a copy of the License at:
 *                             www.st.com/SLA0044
 *
 ******************************************************************************
 */
/* USER CODE END Header */

#include "FreeRTOS.h"
#include "task.h"
#include "main.h"
#include "cmsis_os.h"

/* USER CODE BEGIN Includes */
// ***** Librerías comunes *****
#include <stdio.h>
#include <string.h>
#include <stdlib.h>
#include <stdbool.h>
#include <time.h>

// ***** Librerías del BSP *****
#include "stm32l476g_discovery.h"
#include "stm32l476g_discovery_glass_lcd.h"
#include "stm32l476g_discovery_compass.h"
#include "stm32l476g_discovery_gyroscope.h"

// ***** Librerías de la pantalla oled *****
#include "ssd1306.h"
#include "ssd1306_tests.h"

// ***** Librerías necesarias para los periféricos *****
#include "stm32l4xx_hal.h"
#include "usbd_core.h"
#include "usb_device.h"
#include "fatfs.h"
#include "sai.h"
#include "i2c.h"
/* USER CODE END Includes */

/* USER CODE BEGIN Variables */

// ***** Variables del reproductor *****
#define AUDIO_BUFFER_SIZE          (1024 * 8)       // Tamaño en bytes del buffer con los samples
#define WAV_FILE_HEADER_SIZE        44              // Tamaño en bytes de la cabecera del archivo WAV

// ***** Variables del sistema de archivos Fat y del USB *****
extern FIL                     File;						// Handle del archivo
extern FATFS                   FatFs;						// Handle del sistema de archivos
uint8_t                 Buffer[AUDIO_BUFFER_SIZE];	// Buffer para los samples
uint32_t                ActualPosition;             // Offset de la lectura actual
uint32_t                PrevPosition;               // Offset anterior
USBD_HandleTypeDef	    hUsbDeviceFS;

// ***** Variables de estado del reproductor *****
typedef enum {
	AUDIOPLAYER_STATE_STOPPED = 0,
	AUDIOPLAYER_STATE_RUNNING,
	AUDIOPLAYER_STATE_PAUSED
} AudioPlayer_StateTypeDef;
AudioPlayer_StateTypeDef  AppState = AUDIOPLAYER_STATE_RUNNING;
bool audio_flag = 0;

// ***** Parámetros de la pantalla *****
extern const int width;
extern const int height;

// ***** Parámetros del menu *****
extern SSD1306_COLOR color;	// Color de fondo del texto
extern int menu;	// Indice del menu

// ***** Parámetros del juego *****
extern bool gameover;	// Bandera de Game Over
extern int x, y, score;	// Coordenadas de la pantalla y variable para los puntos
extern int fruitX[3], fruitY[3];	// Arrays con las coordenadas de las frutas
extern int snakeX[256], snakeY[256]; // Arrays con las coordenadas del cuerpo de la serpiente
extern int nTail;	// Número de pixeles que forman la cola de la serpiente
extern int state, prev_state;	// Estado en el que nos encontramos y el anterior a este

/* USER CODE END Variables */
osThreadId gameTaskHandle;
osThreadId usbTaskHandle;
osThreadId audioTaskHandle;
osThreadId inputTaskHandle;
osMessageQId joystickInputQueueHandle;
osMutexId qspiMutexHandle;

/* USER CODE BEGIN FunctionPrototypes */

void Error_Handler(void);

// ***** Funciones de Audio *****
void AudioPlayer_Start(const TCHAR* file_name, bool bg_music, bool aflag);
void AudioPlayer_Pause(void);
void AudioPlayer_Stop(void);
void AudioPlayer_Resume(void);

// ***** Funciones del Juego *****
void Setup();		// Función para establecer las condiciones iniciales
void DrawOled();	// Función para dibujar la pantalla oled
void Algoritmo();	// Función que controla la ejecución del juego
void Fruta();		// Función para crear las frutas en la pantalla
void GameOver();	// Función para el estado de Game Over
void Leaderboard();	// Función para mostrar las mejores puntuaciones conseguidas

void MX_FREERTOS_Init(void); /* (MISRA C 2004 rule 8.1) */
/* USER CODE END FunctionPrototypes */

void gameTaskBody(void const * argument);
void usbTaskBody(void const * argument);
void audioTaskBody(void const * argument);
void inputTaskBody(void const * argument);

extern void MX_USB_DEVICE_Init(void);
void MX_FREERTOS_Init(void); /* (MISRA C 2004 rule 8.1) */

/* GetIdleTaskMemory prototype (linked to static allocation support) */
void vApplicationGetIdleTaskMemory( StaticTask_t **ppxIdleTaskTCBBuffer, StackType_t **ppxIdleTaskStackBuffer, uint32_t *pulIdleTaskStackSize );

/* USER CODE BEGIN GET_IDLE_TASK_MEMORY */
static StaticTask_t xIdleTaskTCBBuffer;
static StackType_t xIdleStack[configMINIMAL_STACK_SIZE];

void vApplicationGetIdleTaskMemory( StaticTask_t **ppxIdleTaskTCBBuffer, StackType_t **ppxIdleTaskStackBuffer, uint32_t *pulIdleTaskStackSize )
{
	*ppxIdleTaskTCBBuffer = &xIdleTaskTCBBuffer;
	*ppxIdleTaskStackBuffer = &xIdleStack[0];
	*pulIdleTaskStackSize = configMINIMAL_STACK_SIZE;
	/* place for user code */
}
/* USER CODE END GET_IDLE_TASK_MEMORY */

void MX_FREERTOS_Init(void) {
  /* Create the mutex(es) */
  /* definition and creation of qspiMutex */
  osMutexDef(qspiMutex);
  qspiMutexHandle = osMutexCreate(osMutex(qspiMutex));

  /* Create the queue(s) */
  /* definition and creation of joystickInputQueue */
  osMessageQDef(joystickInputQueue, 1, uint16_t);
  joystickInputQueueHandle = osMessageCreate(osMessageQ(joystickInputQueue), NULL);

  /* Create the thread(s) */
  /* definition and creation of gameTask */
  osThreadDef(gameTask, gameTaskBody, osPriorityNormal, 0, 4096);
  gameTaskHandle = osThreadCreate(osThread(gameTask), NULL);

  /* definition and creation of usbTask */
  osThreadDef(usbTask, usbTaskBody, osPriorityHigh, 0, 256);
  usbTaskHandle = osThreadCreate(osThread(usbTask), NULL);

  /* definition and creation of audioTask */
  osThreadDef(audioTask, audioTaskBody, osPriorityNormal, 0, 1024);
  audioTaskHandle = osThreadCreate(osThread(audioTask), NULL);

  /* definition and creation of inputTask */
  osThreadDef(inputTask, inputTaskBody, osPriorityNormal, 0, 128);
  inputTaskHandle = osThreadCreate(osThread(inputTask), NULL);

}

void gameTaskBody(void const * argument)
{
  /* init code for USB_DEVICE */
  MX_USB_DEVICE_Init();
  /* USER CODE BEGIN appTaskBody */

	/* Esperamos por el qspiMutex */
	osMutexWait(qspiMutexHandle, osWaitForever);

	/* Montamos el sistema de archivos del módulo FatFs */
	if(f_mount(&FatFs, (TCHAR const*)USERPath, 1) != FR_OK)
	{
		/* Error de inicialización de FatFs */
		if (f_mkfs((TCHAR const*)USERPath, 0, 128, NULL, 0) != FR_OK)
		{
			Error_Handler();
		}
		else {
			/* Segundo intento de montar el sistema de archivos */
			if(f_mount(&FatFs, (TCHAR const*)USERPath, 1) != FR_OK)
			{
				Error_Handler();
			}
		}
	}

	/* Soltamos el qspiMutex */
	osMutexRelease(qspiMutexHandle);

	/* Inicializamos el driver de audio */
	if(CS43L22_ID != AUDIO_ReadID(AUDIO_I2C_ADDRESS))
	{
		Error_Handler();
	}
	if(0 != AUDIO_Init(AUDIO_I2C_ADDRESS, OUTPUT_DEVICE_HEADPHONE, 60, AUDIO_FREQUENCY_44K))
	{
		Error_Handler();
	}

	/* Iniciamos el reproductor */
	AudioPlayer_Start("snake.wav", 0, 0);

	/* Infinite loop */
	for(;;)
	{
		if(gameover == true)
		{
			/* Audio y Pantalla de Game Over */
			AudioPlayer_Start("gameover.wav", 0, 1);
			ssd1306_SetCursor(32, 4);
			ssd1306_WriteString("GAME", Font_16x26, White);
			ssd1306_SetCursor(32, 34);
			ssd1306_WriteString("OVER", Font_16x26, White);
			ssd1306_UpdateScreen();
			osDelay(1500);

			/* Esperamos por el qspiMutex */
			osMutexWait(qspiMutexHandle, osWaitForever);

			GameOver();

			/* Soltamos el qspiMutex */
			osMutexRelease(qspiMutexHandle);
		}
		else
		{
			Algoritmo();	// En caso contrario, calculamos lanueva configuración
			DrawOled();		// y la mostramos por pantalla
		}

		osDelay(100);		// Espera de 100 ms para que el juego no vaya demasiado rápido

	}
  /* USER CODE END appTaskBody */
}

void usbTaskBody(void const * argument)
{
  /* USER CODE BEGIN usbTaskBody */
	uint32_t USB_VBUS_counter = 0;	// Variable del bus USB

	/* Infinite loop */
	for(;;)
	{

		USB_VBUS_counter = 0;
		/* Comprobamos si USB_VBUS está disponible */
		while (USB_VBUS_counter < 5)
		{
			osDelay(10);
			if (HAL_GPIO_ReadPin(USB_VBUS_GPIO_Port, USB_VBUS_Pin) != GPIO_PIN_RESET)
			{
				USB_VBUS_counter++;
			}
			else {
				break;
			}
		}
		if(USB_VBUS_counter >= 5 && menu == 0)
		{

			ssd1306_Init();
			ssd1306_Fill(Black);
			ssd1306_SetCursor(32, 4);
			ssd1306_WriteString("MODO", Font_16x26, White);
			ssd1306_SetCursor(40, 34);
			ssd1306_WriteString("USB", Font_16x26, White);
			ssd1306_UpdateScreen();

			/* Paramos el reproductor de audio, si está funcionando */
			if (AppState != AUDIOPLAYER_STATE_STOPPED)
			{
				AudioPlayer_Stop();
			}

			/* Esperamos por el qspiMutex */
			osMutexWait(qspiMutexHandle, osWaitForever);

			/* Inicializamos el USB */
			MX_USB_DEVICE_Init();

			/* RED LED ON */
			HAL_GPIO_WritePin(LED_RED_GPIO_Port, LED_RED_Pin, GPIO_PIN_SET);

			/* USB_VBUS availability check */
			while (USB_VBUS_counter)
			{
				/* Wait 100ms, then check the USB_VBUS availability */
				osDelay(100);

				if (HAL_GPIO_ReadPin(USB_VBUS_GPIO_Port, USB_VBUS_Pin) == GPIO_PIN_RESET)
				{
					USB_VBUS_counter--;
				}
				else {
					USB_VBUS_counter = 5;
				}
			}

			/* Deinicializamos el USB */
			USBD_DeInit(&hUsbDeviceFS);

			/* Soltamos el qspiMutex */
			osMutexRelease(qspiMutexHandle);

			/* RED LED OFF */
			HAL_GPIO_WritePin(LED_RED_GPIO_Port, LED_RED_Pin, GPIO_PIN_RESET);

			/* Reiniciamos el sistema para recargar la configuración */
			NVIC_SystemReset();
		}
		/* Cada 1 segundo comprobamos si el USB_VBUS está disponible */
		osDelay(1000);
	}
  /* USER CODE END usbTaskBody */
}

void audioTaskBody(void const * argument)
{
  /* USER CODE BEGIN audioTaskBody */
	UINT bufferOffset = 0;	// Offset del buffer
	UINT bytesRead = 0;		// Número de bytes leidos del archivo
	osEvent event;

	/* Pausamos la tarea */
	osThreadSuspend(NULL);

	/* Infinite loop */
	for(;;)
	{
		event = osSignalWait(A | B, osWaitForever);
		if( event.status == osEventSignal )
		{
			switch(event.value.v)
			{
			case B:
				bufferOffset = AUDIO_BUFFER_SIZE/2;	// Offset para el canal B
				break;
			case A:
				bufferOffset = 0;	// Offset para el canal A
				break;
			default:
				/* No somos capaces de streamear más datos => limpiamos el buffer => velocidad de SYSCLK */
				break;
			}

			/* Esperamos por el qspiMutex */
			osMutexWait(qspiMutexHandle, osWaitForever);

			/* Llenamos el buffer con datos */
			if (f_read(&File, (uint8_t *)(Buffer + bufferOffset), AUDIO_BUFFER_SIZE/2, &bytesRead) != FR_OK)
			{
				Error_Handler();
			}

			/* GREEN LED ON */
			HAL_GPIO_TogglePin(LED_GREEN_GPIO_Port, LED_GREEN_Pin);

			ActualPosition += bytesRead;

			/* Comprobamos si se ha llegado al final del archivo */
			if((ActualPosition + (AUDIO_BUFFER_SIZE/2)) > f_size(&File))
			{
				if(audio_flag == 1){	// En caso de no estar reproduciendo la música de fondo entramos aquí

					if (gameover == 1)	// Si estamos en la situación de Game Over necesitamos parar la reproducción
					{
						/* Paramos el playback */
						if (AUDIO_Stop(AUDIO_I2C_ADDRESS, CODEC_PDWN_SW) != 0)
						{
							Error_Handler();
						}
						/* Paramos la transferencia por DMA */
						if (HAL_SAI_DMAStop(&hsai_BlockA1) != HAL_OK)
						{
							Error_Handler();
						}

						osMutexRelease(qspiMutexHandle);	// Soltamos el mutex
						vTaskSuspend( NULL );	// Y suspendemos la tarea
					}

					/* Cerramos el archivo de audio */
					if(f_close(&File) != FR_OK)
					{
						Error_Handler();
					}

					osMutexRelease(qspiMutexHandle);	// Soltamos el mutex

					/* Paramos la transferencia por DMA */
					if (HAL_SAI_DMAStop(&hsai_BlockA1) != HAL_OK)
					{
						Error_Handler();
					}

					AudioPlayer_Start("snake.wav", 1, 0);	// Reiniciamos la reproducción de la música de fondo
				}
				else	// Si está cargada la música de fondo, rebobinamos el
				{		// archivo de audio para reproducirlo desde el principio

					if (f_rewind(&File) != FR_OK)
					{
						Error_Handler();
					}

					if (f_lseek(&File, WAV_FILE_HEADER_SIZE) != FR_OK)
					{
						Error_Handler();
					}

					/* Nos saltamos la cabecera del archivo WAV */
					ActualPosition = WAV_FILE_HEADER_SIZE;
				}
			}

			/* Soltamos el qspiMutex */
			osMutexRelease(qspiMutexHandle);
		}
		else {
			// No hacemos nada :)
		}
	}
  /* USER CODE END audioTaskBody */
}

void inputTaskBody(void const * argument)
{
  /* USER CODE BEGIN inputTaskBody */
	osEvent event;

	/* Infinite loop */
	for(;;)
	{
		if (menu == 1)	// Juego usando el DPAD
		{
			event = osMessageGet(joystickInputQueueHandle, osWaitForever);

			if (event.status == osEventMessage)
			{
				/* Leemos la entrada del DPAD, y cambiamos de estado de acuerdo a eso */
				switch(event.value.v)
				{
					case JOY_LEFT_Pin:
						if(prev_state!=2)
							state = 1;
						break;
					case JOY_RIGHT_Pin:
						if(prev_state!=1)
							state = 2;
						break;
					case JOY_UP_Pin:
						if(prev_state!=4)
							state = 3;
						break;
					case JOY_DOWN_Pin:
						if(prev_state!=3)
							state = 4;
						break;
					case JOY_CENTER_Pin:
						state = 5;
						break;
					default:
						break;
				}
			}
		}
		else if (menu == 2)	// Juego usando el Giroscopio/Acelerómetro
		{
			float axis_gyro[3] = {0};
			float Xval, Yval = 0;
			BSP_GYRO_Reset();	// Recalibramos el giroscopio

			while(1)
			{
				/* Leemos los datos angulares del Giroscopio */
				BSP_GYRO_GetXYZ(axis_gyro);

				/* Damos formato a los nuevos valores y los evaluamos */
				Xval = abs((axis_gyro[0]));
				Yval = abs((axis_gyro[1]));

				if(Xval>Yval){
					if(axis_gyro[0] > 20000.0f){
						//Arriba
						//Evitar que pueda girar 180º
						state = 3;
					}else if(axis_gyro[0] < -20000.0f){
						//Abajo
						state = 4;
					}
				}else if (Yval>Xval){
					if(axis_gyro[1] < -20000.0f){
						//Izquierda
						state = 1;
					}else if(axis_gyro[1] > 20000.0f){
						//Derecha
						state = 2;
					}
				}

			}
		}
	}
  /* USER CODE END inputTaskBody */
}

/* USER CODE BEGIN Application */

/**
 * @brief Application Error Handler
 * @param  None
 * @retval None
 */
//void Error_Handler(void)
//{
//  while(1)
//  {
/* Error management behavior to be added here */
//  }
//}

/**
 * @brief Tx Transfer completed callbacks.
 * @param  hsai : pointer to a SAI_HandleTypeDef structure that contains
 *                the configuration information for SAI module.
 * @retval None
 */
void HAL_SAI_TxCpltCallback(SAI_HandleTypeDef *hsai)
{
	/* NOTE : This function Should not be modified, when the callback is needed,
            the HAL_SAI_TxCpltCallback could be implemented in the user file
	 */
	osSignalSet(audioTaskHandle, B);
}

/**
 * @brief Tx Transfer Half completed callbacks
 * @param  hsai : pointer to a SAI_HandleTypeDef structure that contains
 *                the configuration information for SAI module.
 * @retval None
 */
void HAL_SAI_TxHalfCpltCallback(SAI_HandleTypeDef *hsai)
{
	/* NOTE : This function Should not be modified, when the callback is needed,
            the HAL_SAI_TxHalfCpltCallback could be implenetd in the user file
	 */
	osSignalSet(audioTaskHandle, A);
}

/**
 * @brief AudioPlayer Start method
 * @param  None
 * @retval None
 */
void AudioPlayer_Start(const TCHAR* file_name, bool bg_music, bool aflag)
{
	audio_flag = aflag;

	/* Cargamos el codec de audio y habilitamos su reproducción */
	if(0 != AUDIO_Play(AUDIO_I2C_ADDRESS, NULL, 0))
	{
		Error_Handler();
	}

	/* Esperamos por el qspiMutex */
	osMutexWait(qspiMutexHandle, osWaitForever);

	/* Abrimos el archivo de audio en modo lectura */
	if(f_open(&File, file_name, FA_READ) != FR_OK)
	{
		Error_Handler();
	}

	if (bg_music == 0 )
	{
		/* Nos saltamos la cabacera del archivo WAV */
		PrevPosition = ActualPosition;
		ActualPosition = WAV_FILE_HEADER_SIZE;
	}
	else
	{
		/* Si venimos de una reproducción anterior, seguimos reproduciendo desde donde lo dejamos */
		ActualPosition = PrevPosition;
	}

	/* Movemos el puntero del archivo hasta la dirección correcta */
	if (f_lseek(&File, ActualPosition) != FR_OK)
	{
		Error_Handler();
	}

	/* Soltamos el qspiMutex */
	osMutexRelease(qspiMutexHandle);

	/* Iniciamos la transferencia por el DMA desde el buffer */
	if(HAL_OK != HAL_SAI_Transmit_DMA(&hsai_BlockA1, (uint8_t *)Buffer, AUDIO_BUFFER_SIZE/2))
	{
		Error_Handler();
	}

	/* Cambiamos el estado de la aplicación */
	AppState = AUDIOPLAYER_STATE_RUNNING;

	/* Volvemos a activar la tarea */
	osThreadResume(audioTaskHandle);
}

// *************************************
// ***** Funciones del reproductor *****
// *************************************

/**
 * @brief AudioPlayer Resume method
 * @param  None
 * @retval None
 */
void AudioPlayer_Resume(void)
{
	/* Restablecemos la transferencia por DMA */
	if (HAL_SAI_DMAResume(&hsai_BlockA1) != HAL_OK)
	{
		Error_Handler();
	}
	/* Restablecemos la reproducción */
	if (AUDIO_Resume(AUDIO_I2C_ADDRESS) != 0)
	{
		Error_Handler();
	}

	AppState = AUDIOPLAYER_STATE_RUNNING;

	/* Volvemos a activar la tarea */
	osThreadResume(audioTaskHandle);
}

/**
 * @brief AudioPlayer Pause method
 * @param  None
 * @retval None
 */
void AudioPlayer_Pause(void)
{
	/* Paramos el playback */
	if (AUDIO_Pause(AUDIO_I2C_ADDRESS) != 0)
	{
		Error_Handler();
	}
	/* Paramos la tranferencia por DMA */
	if (HAL_SAI_DMAPause(&hsai_BlockA1) != HAL_OK)
	{
		Error_Handler();
	}

	/* Esperamos por el qspiMutex */
	osMutexWait(qspiMutexHandle, osWaitForever);

	/* Pausamos la tarea */
	osThreadSuspend(audioTaskHandle);

	/* Soltamos el qspiMutex */
	osMutexRelease(qspiMutexHandle);

	/* Apagamos el LED Verde para indicar que ya no hay reproducción de audio */
	HAL_GPIO_WritePin(LED_GREEN_GPIO_Port, LED_GREEN_Pin, GPIO_PIN_RESET);

	/* Cambiamos el estado del reproductor */
	AppState = AUDIOPLAYER_STATE_PAUSED;
}

/**
 * @brief AudioPlayer Stop method
 * @param  None
 * @retval None
 */
void AudioPlayer_Stop(void)
{
	/* Paramos el playback */
	if (AUDIO_Stop(AUDIO_I2C_ADDRESS, CODEC_PDWN_SW) != 0)
	{
		Error_Handler();
	}

	/* Paramos la tranferencia por DMA */
	if (HAL_SAI_DMAStop(&hsai_BlockA1) != HAL_OK)
	{
		Error_Handler();
	}

	/* Esperamos por el qspiMutex */
	osMutexWait(qspiMutexHandle, osWaitForever);

	/* Pausamos la tarea */
	osThreadSuspend(audioTaskHandle);

	/* Cerramos el archivo de audio */
	if(f_close(&File) != FR_OK)
	{
		Error_Handler();
	}

	/* Soltamos el qspiMutex */
	osMutexRelease(qspiMutexHandle);

	/* Apagamos el LED Verde para indicar que ya no hay reproducción de audio */
	HAL_GPIO_WritePin(LED_GREEN_GPIO_Port, LED_GREEN_Pin, GPIO_PIN_RESET);

	AppState = AUDIOPLAYER_STATE_STOPPED;
}

/**
  * @brief  GPIO EXTI Callback function
  *         Handle USB VBUS detection upon External interrupt
  * @param  GPIO_Pin
  * @retval None
  */
void HAL_GPIO_EXTI_Callback(uint16_t GPIO_Pin)
{
  switch (GPIO_Pin) // Usamos las interrupciones para leer la entrada del DPAD
  {
	case JOY_CENTER_Pin:
		osMessagePut(joystickInputQueueHandle, JOY_CENTER_Pin, 0);
		break;
	case JOY_LEFT_Pin:
		osMessagePut(joystickInputQueueHandle, JOY_LEFT_Pin, 0);
		break;
	case JOY_RIGHT_Pin:
		osMessagePut(joystickInputQueueHandle, JOY_RIGHT_Pin, 0);
		break;
	case JOY_UP_Pin:
		osMessagePut(joystickInputQueueHandle, JOY_UP_Pin, 0);
		break;
	case JOY_DOWN_Pin:
		osMessagePut(joystickInputQueueHandle, JOY_DOWN_Pin, 0);
		break;
	default:
		Error_Handler();
		break;
  }
}

/* USER CODE END Application */

/************************ (C) COPYRIGHT STMicroelectronics *****END OF FILE****/
